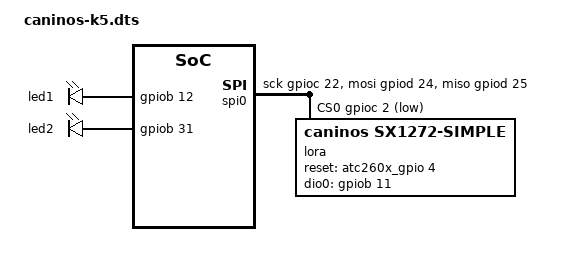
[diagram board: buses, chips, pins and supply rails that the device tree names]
/// SPDX-License-Identifier: (GPL-2.0+ OR MIT)

/dts-v1/;
#include "caninos-k5.dtsi"

/ {
	chosen {
		stdout-path = "serial3:115200n8";
	};

	soc {
		leds {
			compatible = "gpio-leds";
			
			led@1 {
				label = "led1";
				gpios = <&gpiob 12 GPIO_ACTIVE_HIGH>;
				linux,default-trigger = "default-on";
				default-state = "ON";
			};
			
			led@2 {
				label = "led2";
				gpios = <&gpiob 31 GPIO_ACTIVE_HIGH>;
				linux,default-trigger = "heartbeat";
				default-state = "ON";
			};
		};
	};

	spi0: spi-gpio {
		compatible = "spi-gpio";

		#address-cells = <1>;
		#size-cells = <0>;

		mosi-gpios = <&gpiod 24 GPIO_ACTIVE_HIGH>;
		miso-gpios = <&gpiod 25 GPIO_ACTIVE_HIGH>;
		sck-gpios  = <&gpioc 22 GPIO_ACTIVE_HIGH>;
		cs-gpios   = <&gpioc 2  GPIO_ACTIVE_LOW >;
		
		num-chipselects = <1>;
		status = "okay";

		lora@0 {
			compatible = "caninos,sx1272-simple";
			reg = <0>;
			reset-gpios = <&atc260x_gpio 4 GPIO_ACTIVE_HIGH>;
			dio0-gpios = <&gpiob 11 GPIO_ACTIVE_HIGH>;
			pa-boost;
			xtal = <32000000>;
			status = "okay";
		};
	};
};

&mmc1 {
	enable-gpios = <&gpiob 30 GPIO_ACTIVE_HIGH>, 
					<&gpioc 3 GPIO_ACTIVE_HIGH>;
};

&emac {
	phy-power-gpio = <&gpiob 11 GPIO_ACTIVE_HIGH>;
	phy-reset-gpio = <&gpiod 31 GPIO_ACTIVE_HIGH>;
};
